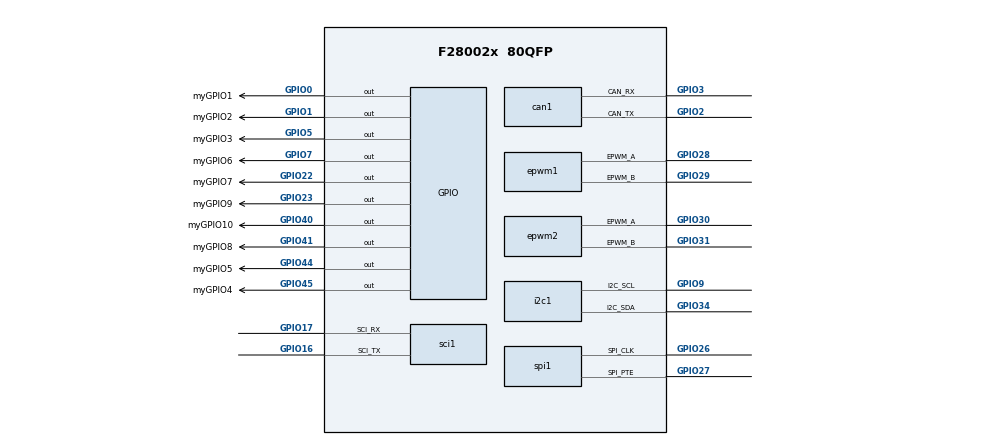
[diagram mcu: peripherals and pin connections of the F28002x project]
/**
 *
 * @cliArgs --device "F28002x" --part "F28002x_80QFP" --package "80QFP" --context "system" --product "C2000WARE@26.01.00.00"
 * @versions {"tool":"1.28.0+4696"}
 */

/**
 * Import the modules used in this configuration.
 */
const adc            = scripting.addModule("/driverlib/adc.js", {}, false);
const adc1           = adc.addInstance();
const can            = scripting.addModule("/driverlib/can.js", {}, false);
const can1           = can.addInstance();
const device_support = scripting.addModule("/driverlib/device_support.js");
const epwm           = scripting.addModule("/driverlib/epwm.js", {}, false);
const epwm1          = epwm.addInstance();
const epwm2          = epwm.addInstance();
const epwm3          = epwm.addInstance();
const gpio           = scripting.addModule("/driverlib/gpio.js", {}, false);
const gpio1          = gpio.addInstance();
const gpio2          = gpio.addInstance();
const gpio3          = gpio.addInstance();
const gpio4          = gpio.addInstance();
const gpio5          = gpio.addInstance();
const gpio6          = gpio.addInstance();
const gpio7          = gpio.addInstance();
const gpio8          = gpio.addInstance();
const gpio9          = gpio.addInstance();
const gpio10         = gpio.addInstance();
const gpio11         = gpio.addInstance();
const i2c            = scripting.addModule("/driverlib/i2c.js", {}, false);
const i2c1           = i2c.addInstance();
const sci            = scripting.addModule("/driverlib/sci.js", {}, false);
const sci1           = sci.addInstance();
const spi            = scripting.addModule("/driverlib/spi.js", {}, false);
const spi1           = spi.addInstance();
const sysctl         = scripting.addModule("/driverlib/sysctl.js");
const CMD            = scripting.addModule("/utilities/cmd_tool/cmd_syscfg/source/CMD");
const CMD1           = CMD.addInstance();
const CMD2           = CMD.addInstance();

/**
 * Write custom configuration values to the imported modules.
 */
adc1.$name = "myADC0";

const analog  = scripting.addModule("/driverlib/analog.js", {}, false);
const analog1 = analog.addInstance({}, false);
analog1.$name = "myANALOGPinMux0";
adc1.analog   = analog1;

can1.$name                 = "myCAN0";
can1.can.can_rxPin.$assign = "GPIO3";
can1.can.can_txPin.$assign = "GPIO2";

epwm1.$name                  = "myEPWM0";
epwm1.epwm.$assign           = "EPWM7";
epwm1.epwm.epwm_aPin.$assign = "GPIO28";
epwm1.epwm.epwm_bPin.$assign = "GPIO29";

epwm2.$name                  = "myEPWM1";
epwm2.epwm.epwm_aPin.$assign = "GPIO30";
epwm2.epwm.epwm_bPin.$assign = "GPIO31";

epwm3.$name        = "myEPWM2";
epwm3.epwm.$assign = "EPWM3";

gpio1.$name = "myGPIO0";

gpio2.$name           = "myGPIO3";
gpio2.gpioPin.$assign = "GPIO5";

gpio3.$name           = "myGPIO4";
gpio3.gpioPin.$assign = "GPIO45";

gpio4.$name           = "myGPIO5";
gpio4.gpioPin.$assign = "GPIO44";

gpio5.$name           = "myGPIO6";
gpio5.gpioPin.$assign = "GPIO7";

gpio6.$name           = "myGPIO7";
gpio6.gpioPin.$assign = "GPIO22";

gpio7.$name           = "myGPIO8";
gpio7.gpioPin.$assign = "GPIO41";

gpio8.$name           = "myGPIO9";
gpio8.gpioPin.$assign = "GPIO23";

gpio9.$name           = "myGPIO10";
gpio9.gpioPin.$assign = "GPIO40";

gpio10.$name           = "myGPIO1";
gpio10.gpioPin.$assign = "GPIO0";

gpio11.$name           = "myGPIO2";
gpio11.gpioPin.$assign = "GPIO1";

i2c1.$name                  = "myI2C0";
i2c1.i2c.$assign            = "I2CB";
i2c1.i2c.i2c_sdaPin.$assign = "GPIO34";
i2c1.i2c.i2c_sclPin.$assign = "GPIO9";

sci1.$name                 = "mySCI0";
sci1.sci.sci_rxPin.$assign = "GPIO17";
sci1.sci.sci_txPin.$assign = "GPIO16";
sci1.rxQual.$name          = "myGPIOQUAL0";
sci1.txQual.$name          = "myGPIOQUAL1";

spi1.$name                  = "mySPI0";
spi1.spi.$assign            = "SPIB";
spi1.spi.spi_clkPin.$assign = "GPIO26";
spi1.spi.spi_ptePin.$assign = "GPIO27";
spi1.picoQual.$name         = "myGPIOQUAL2";
spi1.pociQual.$name         = "myGPIOQUAL3";
spi1.clkQual.$name          = "myGPIOQUAL4";
spi1.pteQual.$name          = "myGPIOQUAL5";

CMD1.$name                    = "generic_ram_lnk";
CMD1.sectionMemory_text       = ["RAMGS0","RAMLS4","RAMLS5","RAMLS6","RAMLS7"];
CMD1.sectionMemory_ramfunc    = ["RAMM0"];
CMD1.sectionMemory_cinit      = ["RAMM0"];
CMD1.sectionMemory_stack      = ["RAMM1"];
CMD1.sectionMemory_init_array = ["RAMM0"];
CMD1.sectionMemory_bss        = ["RAMLS4"];
CMD1.sectionMemory_const      = ["RAMLS4"];
CMD1.sectionMemory_data       = ["RAMLS4"];
CMD1.sectionMemory_switch     = ["RAMM0"];
CMD1.sectionMemory_sysmem     = ["RAMLS4"];
CMD1.sectionRun_ramfunc       = ["RAMLS4"];

CMD2.$name                               = "generic_flash_lnk";
CMD2.sectionAlignEnable_ramfunc          = true;
CMD2.sectionAlignEnable_text             = true;
CMD2.sectionAlignEnable_binit            = true;
CMD2.sectionAlignEnable_cinit            = true;
CMD2.sectionAlignEnable_switch           = true;
CMD2.sectionAlignEnable_init_array       = true;
CMD2.sectionAlignEnable_const            = true;
CMD2.sectionAlignEnable_ovly             = true;
CMD2.sectionMemory_codestart             = "0x080000";
CMD2.sectionMemory_stack                 = ["RAMM1"];
CMD2.sectionMemory_ramfunc               = ["FLASH_BANK0_SEC1"];
CMD2.sectionMemory_text                  = ["FLASH_BANK0_SEC2","FLASH_BANK0_SEC3","FLASH_BANK0_SEC4"];
CMD2.sectionMemory_binit                 = ["FLASH_BANK0_SEC1"];
CMD2.sectionMemory_cinit                 = ["FLASH_BANK0_SEC1"];
CMD2.sectionMemory_switch                = ["FLASH_BANK0_SEC1"];
CMD2.sectionMemory_bss                   = ["RAMLS5"];
CMD2.sectionMemory_data                  = ["RAMLS5"];
CMD2.sectionMemory_sysmem                = ["RAMLS5"];
CMD2.sectionRunFromDifferentAddr_ramfunc = true;
CMD2.sectionBinit_ramfunc                = false;
CMD2.sectionMemory_init_array            = ["FLASH_BANK0_SEC1"];
CMD2.sectionMemory_const                 = ["FLASH_BANK0_SEC4"];
CMD2.sectionMemory_ovly                  = ["FLASH_BANK0_SEC1"];

/**
 * Pinmux solution for unlocked pins/peripherals. This ensures that minor changes to the automatic solver in a future
 * version of the tool will not impact the pinmux you originally saw.  These lines can be completely deleted in order to
 * re-solve from scratch.
 */
analog1.analog.$suggestSolution                  = "ANALOG";
analog1.analog["a0/c15Pin"].$suggestSolution     = "A0/C15";
analog1.analog.a1Pin.$suggestSolution            = "A1";
analog1.analog["a10/c10Pin"].$suggestSolution    = "A10/C10";
analog1.analog["a11/c0Pin"].$suggestSolution     = "A11/C0";
analog1.analog["a12/c1Pin"].$suggestSolution     = "A12/C1";
analog1.analog["a14/c4Pin"].$suggestSolution     = "A14/C4";
analog1.analog["a15/c7Pin"].$suggestSolution     = "A15/C7";
analog1.analog["a2/c9Pin"].$suggestSolution      = "A2/C9";
analog1.analog["a3/c5/vdacPin"].$suggestSolution = "A3/C5/VDAC";
analog1.analog["a4/c14Pin"].$suggestSolution     = "A4/C14";
analog1.analog["a5/c2Pin"].$suggestSolution      = "A5/C2";
analog1.analog.a6Pin.$suggestSolution            = "A6";
analog1.analog["a7/c3Pin"].$suggestSolution      = "A7/C3";
analog1.analog["a8/c11Pin"].$suggestSolution     = "A8/C11";
analog1.analog["a9/c8Pin"].$suggestSolution      = "A9/C8";
analog1.analog.c6Pin.$suggestSolution            = "C6";
can1.can.$suggestSolution                        = "CANA";
epwm2.epwm.$suggestSolution                      = "EPWM1";
epwm3.epwm.epwm_aPin.$suggestSolution            = "GPIO14";
epwm3.epwm.epwm_bPin.$suggestSolution            = "GPIO15";
gpio1.gpioPin.$suggestSolution                   = "GPIO46";
sci1.sci.$suggestSolution                        = "SCIA";
spi1.spi.spi_picoPin.$suggestSolution            = "GPIO24";
spi1.spi.spi_pociPin.$suggestSolution            = "GPIO25";
